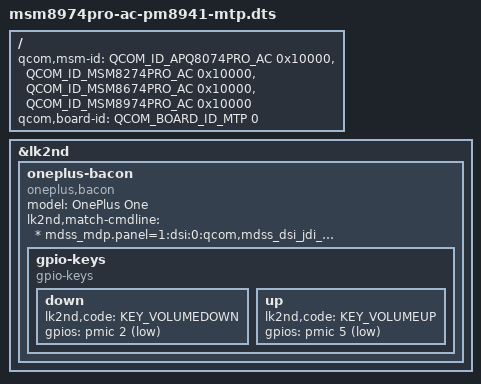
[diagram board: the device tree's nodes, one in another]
// SPDX-License-Identifier: BSD-3-Clause

#include <skeleton64.dtsi>
#include <lk2nd.dtsi>

/ {
	qcom,msm-id = <QCOM_ID_APQ8074PRO_AC 0x10000>,
		      <QCOM_ID_MSM8274PRO_AC 0x10000>,
		      <QCOM_ID_MSM8674PRO_AC 0x10000>,
		      <QCOM_ID_MSM8974PRO_AC 0x10000>;

	qcom,board-id = <QCOM_BOARD_ID_MTP 0>;
};

&lk2nd {
	oneplus-bacon {
		model = "OnePlus One";
		compatible = "oneplus,bacon";
		lk2nd,match-cmdline = "* mdss_mdp.panel=1:dsi:0:qcom,mdss_dsi_jdi_1080p_cmd *";

		//FIXME: lk2nd,dtb-files = "msm8974pro-oneplus-bacon";

		gpio-keys {
			compatible = "gpio-keys";
			down {
				lk2nd,code = <KEY_VOLUMEDOWN>;
				gpios = <&pmic 2 (GPIO_ACTIVE_LOW | GPIO_PULL_UP)>;
			};

			up {
				lk2nd,code = <KEY_VOLUMEUP>;
				gpios = <&pmic 5 (GPIO_ACTIVE_LOW | GPIO_PULL_UP)>;
			};
		};
	};
};

